AUTOSAR XML (schema 4.0)
package /If
  sender receiver interface SrSpeedIf
    data Speed
  sender receiver interface SrStatusIf
    data Status
package /SwComponentType
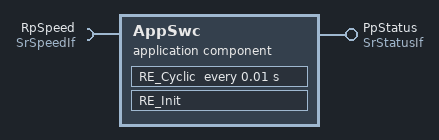
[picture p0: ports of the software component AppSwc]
  application sw component type AppSwc
    provide port PpStatus: provided-interface=SrStatusIf
    require port RpSpeed: required-interface=SrSpeedIf
    behavior IB_AppSwc
      init event EvInit: start-on-event=RE_Init
      timing event EvCyclic10ms: start-on-event=RE_Cyclic, period=0.01, offset=0
      runnable RE_Init: symbol=AppSwc_Init
      runnable RE_Cyclic: symbol=AppSwc_Cyclic
        data-receive-point-by-arguments:
          access DRP_RpSpeed_Speed: accessed-variable=RpSpeed.Speed
        data-send-points:
          access DSP_PpStatus_Status: accessed-variable=PpStatus.Status
  composition sw component type TopComp
    component app: type=AppSwc
